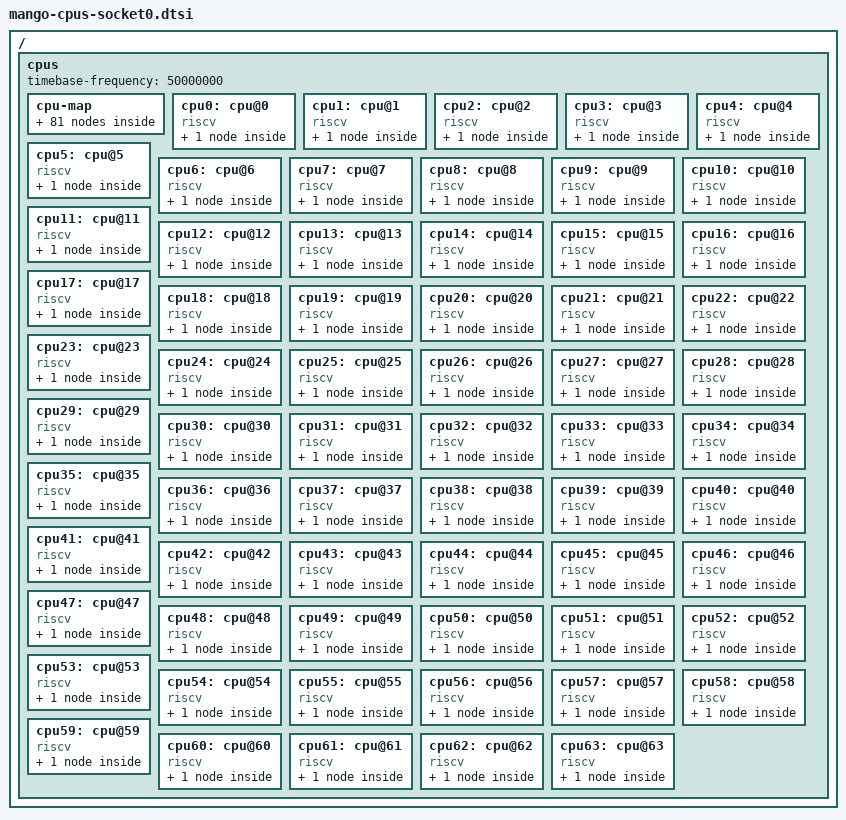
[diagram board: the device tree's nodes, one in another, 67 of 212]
/ {
	cpus {
		#address-cells = <1>;
		#size-cells = <0>;
		timebase-frequency = <50000000>;

		cpu-map {
			socket0 {
				cluster0 {
					 core0 {
						cpu = <&cpu0>;
					 };
					 core1 {
						cpu = <&cpu1>;
					 };
					 core2 {
						cpu = <&cpu2>;
					 };
					 core3 {
						cpu = <&cpu3>;
					 };
				};

				cluster1 {
					 core0 {
						cpu = <&cpu4>;
					 };
					 core1 {
						cpu = <&cpu5>;
					 };
					 core2 {
						cpu = <&cpu6>;
					 };
					 core3 {
						cpu = <&cpu7>;
					 };
				};

				cluster2 {
					 core0 {
						cpu = <&cpu16>;
					 };
					 core1 {
						cpu = <&cpu17>;
					 };
					 core2 {
						cpu = <&cpu18>;
					 };
					 core3 {
						cpu = <&cpu19>;
					 };
				};

				cluster3 {
					 core0 {
						cpu = <&cpu20>;
					 };
					 core1 {
						cpu = <&cpu21>;
					 };
					 core2 {
						cpu = <&cpu22>;
					 };
					 core3 {
						cpu = <&cpu23>;
					 };
				};

				cluster4 {
					 core0 {
						cpu = <&cpu8>;
					 };
					 core1 {
						cpu = <&cpu9>;
					 };
					 core2 {
						cpu = <&cpu10>;
					 };
					 core3 {
						cpu = <&cpu11>;
					 };
				};

				cluster5 {
					 core0 {
						cpu = <&cpu12>;
					 };
					 core1 {
						cpu = <&cpu13>;
					 };
					 core2 {
						cpu = <&cpu14>;
					 };
					 core3 {
						cpu = <&cpu15>;
					 };
				};

				cluster6 {
					 core0 {
						cpu = <&cpu24>;
					 };
					 core1 {
						cpu = <&cpu25>;
					 };
					 core2 {
						cpu = <&cpu26>;
					 };
					 core3 {
						cpu = <&cpu27>;
					 };
				};

				cluster7 {
					 core0 {
						cpu = <&cpu28>;
					 };
					 core1 {
						cpu = <&cpu29>;
					 };
					 core2 {
						cpu = <&cpu30>;
					 };
					 core3 {
						cpu = <&cpu31>;
					 };
				};

				cluster8 {
					 core0 {
						cpu = <&cpu32>;
					 };
					 core1 {
						cpu = <&cpu33>;
					 };
					 core2 {
						cpu = <&cpu34>;
					 };
					 core3 {
						cpu = <&cpu35>;
					 };
				};

				cluster9 {
					 core0 {
						cpu = <&cpu36>;
					 };
					 core1 {
						cpu = <&cpu37>;
					 };
					 core2 {
						cpu = <&cpu38>;
					 };
					 core3 {
						cpu = <&cpu39>;
					 };
				};

				cluster10 {
					 core0 {
						cpu = <&cpu48>;
					 };
					 core1 {
						cpu = <&cpu49>;
					 };
					 core2 {
						cpu = <&cpu50>;
					 };
					 core3 {
						cpu = <&cpu51>;
					 };
				};

				cluster11 {
					 core0 {
						cpu = <&cpu52>;
					 };
					 core1 {
						cpu = <&cpu53>;
					 };
					 core2 {
						cpu = <&cpu54>;
					 };
					 core3 {
						cpu = <&cpu55>;
					 };
				};

				cluster12 {
					 core0 {
						cpu = <&cpu40>;
					 };
					 core1 {
						cpu = <&cpu41>;
					 };
					 core2 {
						cpu = <&cpu42>;
					 };
					 core3 {
						cpu = <&cpu43>;
					 };
				};

				cluster13 {
					 core0 {
						cpu = <&cpu44>;
					 };
					 core1 {
						cpu = <&cpu45>;
					 };
					 core2 {
						cpu = <&cpu46>;
					 };
					 core3 {
						cpu = <&cpu47>;
					 };
				};

				cluster14 {
					 core0 {
						cpu = <&cpu56>;
					 };
					 core1 {
						cpu = <&cpu57>;
					 };
					 core2 {
						cpu = <&cpu58>;
					 };
					 core3 {
						cpu = <&cpu59>;
					 };
				};

				cluster15 {
					 core0 {
						cpu = <&cpu60>;
					 };
					 core1 {
						cpu = <&cpu61>;
					 };
					 core2 {
						cpu = <&cpu62>;
					 };
					 core3 {
						cpu = <&cpu63>;
					 };
				};
			};
		};

		cpu0: cpu@0 {
			device_type = "cpu";
			reg = <0>;
			status = "okay";
			compatible = "riscv";
			riscv,isa = "rv64imafdcv";
			mmu-type = "riscv,sv39";
			numa-node-id = <0>;
			cpu0_intc: interrupt-controller {
				#interrupt-cells = <1>;
				compatible = "riscv,cpu-intc";
				interrupt-controller;
			};
		};
		cpu1: cpu@1 {
			device_type = "cpu";
			reg = <1>;
			status = "okay";
			compatible = "riscv";
			riscv,isa = "rv64imafdcv";
			mmu-type = "riscv,sv39";
			numa-node-id = <0>;
			cpu1_intc: interrupt-controller {
				#interrupt-cells = <1>;
				compatible = "riscv,cpu-intc";
				interrupt-controller;
			};
		};
		cpu2: cpu@2 {
			device_type = "cpu";
			reg = <2>;
			status = "okay";
			compatible = "riscv";
			riscv,isa = "rv64imafdcv";
			mmu-type = "riscv,sv39";
			numa-node-id = <0>;
			cpu2_intc: interrupt-controller {
				#interrupt-cells = <1>;
				compatible = "riscv,cpu-intc";
				interrupt-controller;
			};
		};
		cpu3: cpu@3 {
			device_type = "cpu";
			reg = <3>;
			status = "okay";
			compatible = "riscv";
			riscv,isa = "rv64imafdcv";
			mmu-type = "riscv,sv39";
			numa-node-id = <0>;
			cpu3_intc: interrupt-controller {
				#interrupt-cells = <1>;
				compatible = "riscv,cpu-intc";
				interrupt-controller;
			};
		};
		cpu4: cpu@4 {
			device_type = "cpu";
			reg = <4>;
			status = "okay";
			compatible = "riscv";
			riscv,isa = "rv64imafdcv";
			mmu-type = "riscv,sv39";
			numa-node-id = <0>;
			cpu4_intc: interrupt-controller {
				#interrupt-cells = <1>;
				compatible = "riscv,cpu-intc";
				interrupt-controller;
			};
		};
		cpu5: cpu@5 {
			device_type = "cpu";
			reg = <5>;
			status = "okay";
			compatible = "riscv";
			riscv,isa = "rv64imafdcv";
			mmu-type = "riscv,sv39";
			numa-node-id = <0>;
			cpu5_intc: interrupt-controller {
				#interrupt-cells = <1>;
				compatible = "riscv,cpu-intc";
				interrupt-controller;
			};
		};
		cpu6: cpu@6 {
			device_type = "cpu";
			reg = <6>;
			status = "okay";
			compatible = "riscv";
			riscv,isa = "rv64imafdcv";
			mmu-type = "riscv,sv39";
			numa-node-id = <0>;
			cpu6_intc: interrupt-controller {
				#interrupt-cells = <1>;
				compatible = "riscv,cpu-intc";
				interrupt-controller;
			};
		};
		cpu7: cpu@7 {
			device_type = "cpu";
			reg = <7>;
			status = "okay";
			compatible = "riscv";
			riscv,isa = "rv64imafdcv";
			mmu-type = "riscv,sv39";
			numa-node-id = <0>;
			cpu7_intc: interrupt-controller {
				#interrupt-cells = <1>;
				compatible = "riscv,cpu-intc";
				interrupt-controller;
			};
		};
		cpu8: cpu@8 {
			device_type = "cpu";
			reg = <8>;
			status = "okay";
			compatible = "riscv";
			riscv,isa = "rv64imafdcv";
			mmu-type = "riscv,sv39";
			numa-node-id = <1>;
			cpu8_intc: interrupt-controller {
				#interrupt-cells = <1>;
				compatible = "riscv,cpu-intc";
				interrupt-controller;
			};
		};
		cpu9: cpu@9 {
			device_type = "cpu";
			reg = <9>;
			status = "okay";
			compatible = "riscv";
			riscv,isa = "rv64imafdcv";
			mmu-type = "riscv,sv39";
			numa-node-id = <1>;
			cpu9_intc: interrupt-controller {
				#interrupt-cells = <1>;
				compatible = "riscv,cpu-intc";
				interrupt-controller;
			};
		};
		cpu10: cpu@10 {
			device_type = "cpu";
			reg = <10>;
			status = "okay";
			compatible = "riscv";
			riscv,isa = "rv64imafdcv";
			mmu-type = "riscv,sv39";
			numa-node-id = <1>;
			cpu10_intc: interrupt-controller {
				#interrupt-cells = <1>;
				compatible = "riscv,cpu-intc";
				interrupt-controller;
			};
		};
		cpu11: cpu@11 {
			device_type = "cpu";
			reg = <11>;
			status = "okay";
			compatible = "riscv";
			riscv,isa = "rv64imafdcv";
			mmu-type = "riscv,sv39";
			numa-node-id = <1>;
			cpu11_intc: interrupt-controller {
				#interrupt-cells = <1>;
				compatible = "riscv,cpu-intc";
				interrupt-controller;
			};
		};
		cpu12: cpu@12 {
			device_type = "cpu";
			reg = <12>;
			status = "okay";
			compatible = "riscv";
			riscv,isa = "rv64imafdcv";
			mmu-type = "riscv,sv39";
			numa-node-id = <1>;
			cpu12_intc: interrupt-controller {
				#interrupt-cells = <1>;
				compatible = "riscv,cpu-intc";
				interrupt-controller;
			};
		};
		cpu13: cpu@13 {
			device_type = "cpu";
			reg = <13>;
			status = "okay";
			compatible = "riscv";
			riscv,isa = "rv64imafdcv";
			mmu-type = "riscv,sv39";
			numa-node-id = <1>;
			cpu13_intc: interrupt-controller {
				#interrupt-cells = <1>;
				compatible = "riscv,cpu-intc";
				interrupt-controller;
			};
		};
		cpu14: cpu@14 {
			device_type = "cpu";
			reg = <14>;
			status = "okay";
			compatible = "riscv";
			riscv,isa = "rv64imafdcv";
			mmu-type = "riscv,sv39";
			numa-node-id = <1>;
			cpu14_intc: interrupt-controller {
				#interrupt-cells = <1>;
				compatible = "riscv,cpu-intc";
				interrupt-controller;
			};
		};
		cpu15: cpu@15 {
			device_type = "cpu";
			reg = <15>;
			status = "okay";
			compatible = "riscv";
			riscv,isa = "rv64imafdcv";
			mmu-type = "riscv,sv39";
			numa-node-id = <1>;
			cpu15_intc: interrupt-controller {
				#interrupt-cells = <1>;
				compatible = "riscv,cpu-intc";
				interrupt-controller;
			};
		};
		cpu16: cpu@16 {
			device_type = "cpu";
			reg = <16>;
			status = "okay";
			compatible = "riscv";
			riscv,isa = "rv64imafdcv";
			mmu-type = "riscv,sv39";
			numa-node-id = <0>;
			cpu16_intc: interrupt-controller {
				#interrupt-cells = <1>;
				compatible = "riscv,cpu-intc";
				interrupt-controller;
			};
		};
		cpu17: cpu@17 {
			device_type = "cpu";
			reg = <17>;
			status = "okay";
			compatible = "riscv";
			riscv,isa = "rv64imafdcv";
			mmu-type = "riscv,sv39";
			numa-node-id = <0>;
			cpu17_intc: interrupt-controller {
				#interrupt-cells = <1>;
				compatible = "riscv,cpu-intc";
				interrupt-controller;
			};
		};
		cpu18: cpu@18 {
			device_type = "cpu";
			reg = <18>;
			status = "okay";
			compatible = "riscv";
			riscv,isa = "rv64imafdcv";
			mmu-type = "riscv,sv39";
			numa-node-id = <0>;
			cpu18_intc: interrupt-controller {
				#interrupt-cells = <1>;
				compatible = "riscv,cpu-intc";
				interrupt-controller;
			};
		};
		cpu19: cpu@19 {
			device_type = "cpu";
			reg = <19>;
			status = "okay";
			compatible = "riscv";
			riscv,isa = "rv64imafdcv";
			mmu-type = "riscv,sv39";
			numa-node-id = <0>;
			cpu19_intc: interrupt-controller {
				#interrupt-cells = <1>;
				compatible = "riscv,cpu-intc";
				interrupt-controller;
			};
		};
		cpu20: cpu@20 {
			device_type = "cpu";
			reg = <20>;
			status = "okay";
			compatible = "riscv";
			riscv,isa = "rv64imafdcv";
			mmu-type = "riscv,sv39";
			numa-node-id = <0>;
			cpu20_intc: interrupt-controller {
				#interrupt-cells = <1>;
				compatible = "riscv,cpu-intc";
				interrupt-controller;
			};
		};
		cpu21: cpu@21 {
			device_type = "cpu";
			reg = <21>;
			status = "okay";
			compatible = "riscv";
			riscv,isa = "rv64imafdcv";
			mmu-type = "riscv,sv39";
			numa-node-id = <0>;
			cpu21_intc: interrupt-controller {
				#interrupt-cells = <1>;
				compatible = "riscv,cpu-intc";
				interrupt-controller;
			};
		};
		cpu22: cpu@22 {
			device_type = "cpu";
			reg = <22>;
			status = "okay";
			compatible = "riscv";
			riscv,isa = "rv64imafdcv";
			mmu-type = "riscv,sv39";
			numa-node-id = <0>;
			cpu22_intc: interrupt-controller {
				#interrupt-cells = <1>;
				compatible = "riscv,cpu-intc";
				interrupt-controller;
			};
		};
		cpu23: cpu@23 {
			device_type = "cpu";
			reg = <23>;
			status = "okay";
			compatible = "riscv";
			riscv,isa = "rv64imafdcv";
			mmu-type = "riscv,sv39";
			numa-node-id = <0>;
			cpu23_intc: interrupt-controller {
				#interrupt-cells = <1>;
				compatible = "riscv,cpu-intc";
				interrupt-controller;
			};
		};
		cpu24: cpu@24 {
			device_type = "cpu";
			reg = <24>;
			status = "okay";
			compatible = "riscv";
			riscv,isa = "rv64imafdcv";
			mmu-type = "riscv,sv39";
			numa-node-id = <1>;
			cpu24_intc: interrupt-controller {
				#interrupt-cells = <1>;
				compatible = "riscv,cpu-intc";
				interrupt-controller;
			};
		};
		cpu25: cpu@25 {
			device_type = "cpu";
			reg = <25>;
			status = "okay";
			compatible = "riscv";
			riscv,isa = "rv64imafdcv";
			mmu-type = "riscv,sv39";
			numa-node-id = <1>;
			cpu25_intc: interrupt-controller {
				#interrupt-cells = <1>;
				compatible = "riscv,cpu-intc";
				interrupt-controller;
			};
		};
		cpu26: cpu@26 {
			device_type = "cpu";
			reg = <26>;
			status = "okay";
			compatible = "riscv";
			riscv,isa = "rv64imafdcv";
			mmu-type = "riscv,sv39";
			numa-node-id = <1>;
			cpu26_intc: interrupt-controller {
				#interrupt-cells = <1>;
				compatible = "riscv,cpu-intc";
				interrupt-controller;
			};
		};
		cpu27: cpu@27 {
			device_type = "cpu";
			reg = <27>;
			status = "okay";
			compatible = "riscv";
			riscv,isa = "rv64imafdcv";
			mmu-type = "riscv,sv39";
			numa-node-id = <1>;
			cpu27_intc: interrupt-controller {
				#interrupt-cells = <1>;
				compatible = "riscv,cpu-intc";
				interrupt-controller;
			};
		};
		cpu28: cpu@28 {
			device_type = "cpu";
			reg = <28>;
			status = "okay";
			compatible = "riscv";
			riscv,isa = "rv64imafdcv";
			mmu-type = "riscv,sv39";
			numa-node-id = <1>;
			cpu28_intc: interrupt-controller {
				#interrupt-cells = <1>;
				compatible = "riscv,cpu-intc";
				interrupt-controller;
			};
		};
		cpu29: cpu@29 {
			device_type = "cpu";
			reg = <29>;
			status = "okay";
			compatible = "riscv";
			riscv,isa = "rv64imafdcv";
			mmu-type = "riscv,sv39";
			numa-node-id = <1>;
			cpu29_intc: interrupt-controller {
				#interrupt-cells = <1>;
				compatible = "riscv,cpu-intc";
				interrupt-controller;
			};
		};
		cpu30: cpu@30 {
			device_type = "cpu";
			reg = <30>;
			status = "okay";
			compatible = "riscv";
			riscv,isa = "rv64imafdcv";
			mmu-type = "riscv,sv39";
			numa-node-id = <1>;
			cpu30_intc: interrupt-controller {
				#interrupt-cells = <1>;
				compatible = "riscv,cpu-intc";
				interrupt-controller;
			};
		};
		cpu31: cpu@31 {
			device_type = "cpu";
			reg = <31>;
			status = "okay";
			compatible = "riscv";
			riscv,isa = "rv64imafdcv";
			mmu-type = "riscv,sv39";
			numa-node-id = <1>;
			cpu31_intc: interrupt-controller {
				#interrupt-cells = <1>;
				compatible = "riscv,cpu-intc";
				interrupt-controller;
			};
		};
		cpu32: cpu@32 {
			device_type = "cpu";
			reg = <32>;
			status = "okay";
			compatible = "riscv";
			riscv,isa = "rv64imafdcv";
			mmu-type = "riscv,sv39";
			numa-node-id = <2>;
			cpu32_intc: interrupt-controller {
				#interrupt-cells = <1>;
				compatible = "riscv,cpu-intc";
				interrupt-controller;
			};
		};
		cpu33: cpu@33 {
			device_type = "cpu";
			reg = <33>;
			status = "okay";
			compatible = "riscv";
			riscv,isa = "rv64imafdcv";
			mmu-type = "riscv,sv39";
			numa-node-id = <2>;
			cpu33_intc: interrupt-controller {
				#interrupt-cells = <1>;
				compatible = "riscv,cpu-intc";
				interrupt-controller;
			};
		};
		cpu34: cpu@34 {
			device_type = "cpu";
			reg = <34>;
			status = "okay";
			compatible = "riscv";
			riscv,isa = "rv64imafdcv";
			mmu-type = "riscv,sv39";
			numa-node-id = <2>;
			cpu34_intc: interrupt-controller {
				#interrupt-cells = <1>;
				compatible = "riscv,cpu-intc";
				interrupt-controller;
			};
		};
		cpu35: cpu@35 {
			device_type = "cpu";
			reg = <35>;
			status = "okay";
			compatible = "riscv";
			riscv,isa = "rv64imafdcv";
			mmu-type = "riscv,sv39";
			numa-node-id = <2>;
			cpu35_intc: interrupt-controller {
				#interrupt-cells = <1>;
				compatible = "riscv,cpu-intc";
				interrupt-controller;
			};
		};
		cpu36: cpu@36 {
			device_type = "cpu";
			reg = <36>;
			status = "okay";
			compatible = "riscv";
			riscv,isa = "rv64imafdcv";
			mmu-type = "riscv,sv39";
			numa-node-id = <2>;
			cpu36_intc: interrupt-controller {
				#interrupt-cells = <1>;
				compatible = "riscv,cpu-intc";
				interrupt-controller;
			};
		};
		cpu37: cpu@37 {
			device_type = "cpu";
			reg = <37>;
			status = "okay";
			compatible = "riscv";
			riscv,isa = "rv64imafdcv";
			mmu-type = "riscv,sv39";
			numa-node-id = <2>;
			cpu37_intc: interrupt-controller {
				#interrupt-cells = <1>;
				compatible = "riscv,cpu-intc";
				interrupt-controller;
			};
		};
		cpu38: cpu@38 {
			device_type = "cpu";
			reg = <38>;
			status = "okay";
			compatible = "riscv";
			riscv,isa = "rv64imafdcv";
			mmu-type = "riscv,sv39";
			numa-node-id = <2>;
			cpu38_intc: interrupt-controller {
				#interrupt-cells = <1>;
				compatible = "riscv,cpu-intc";
				interrupt-controller;
			};
		};
		cpu39: cpu@39 {
			device_type = "cpu";
			reg = <39>;
			status = "okay";
			compatible = "riscv";
			riscv,isa = "rv64imafdcv";
			mmu-type = "riscv,sv39";
			numa-node-id = <2>;
			cpu39_intc: interrupt-controller {
				#interrupt-cells = <1>;
				compatible = "riscv,cpu-intc";
				interrupt-controller;
			};
		};
		cpu40: cpu@40 {
			device_type = "cpu";
			reg = <40>;
			status = "okay";
			compatible = "riscv";
			riscv,isa = "rv64imafdcv";
			mmu-type = "riscv,sv39";
			numa-node-id = <3>;
			cpu40_intc: interrupt-controller {
				#interrupt-cells = <1>;
				compatible = "riscv,cpu-intc";
				interrupt-controller;
			};
		};
		cpu41: cpu@41 {
			device_type = "cpu";
			reg = <41>;
			status = "okay";
			compatible = "riscv";
			riscv,isa = "rv64imafdcv";
			mmu-type = "riscv,sv39";
			numa-node-id = <3>;
			cpu41_intc: interrupt-controller {
				#interrupt-cells = <1>;
				compatible = "riscv,cpu-intc";
				interrupt-controller;
			};
		};
		cpu42: cpu@42 {
			device_type = "cpu";
			reg = <42>;
			status = "okay";
			compatible = "riscv";
			riscv,isa = "rv64imafdcv";
			mmu-type = "riscv,sv39";
			numa-node-id = <3>;
			cpu42_intc: interrupt-controller {
				#interrupt-cells = <1>;
				compatible = "riscv,cpu-intc";
				interrupt-controller;
			};
		};
		cpu43: cpu@43 {
			device_type = "cpu";
			reg = <43>;
			status = "okay";
			compatible = "riscv";
			riscv,isa = "rv64imafdcv";
			mmu-type = "riscv,sv39";
			numa-node-id = <3>;
			cpu43_intc: interrupt-controller {
				#interrupt-cells = <1>;
				compatible = "riscv,cpu-intc";
				interrupt-controller;
			};
		};
		cpu44: cpu@44 {
			device_type = "cpu";
			reg = <44>;
			status = "okay";
			compatible = "riscv";
			riscv,isa = "rv64imafdcv";
			mmu-type = "riscv,sv39";
			numa-node-id = <3>;
			cpu44_intc: interrupt-controller {
				#interrupt-cells = <1>;
				compatible = "riscv,cpu-intc";
				interrupt-controller;
			};
		};
		cpu45: cpu@45 {
			device_type = "cpu";
			reg = <45>;
			status = "okay";
			compatible = "riscv";
			riscv,isa = "rv64imafdcv";
			mmu-type = "riscv,sv39";
			numa-node-id = <3>;
			cpu45_intc: interrupt-controller {
				#interrupt-cells = <1>;
				compatible = "riscv,cpu-intc";
				interrupt-controller;
			};
		};
		cpu46: cpu@46 {
			device_type = "cpu";
			reg = <46>;
			status = "okay";
			compatible = "riscv";
			riscv,isa = "rv64imafdcv";
			mmu-type = "riscv,sv39";
			numa-node-id = <3>;
			cpu46_intc: interrupt-controller {
				#interrupt-cells = <1>;
				compatible = "riscv,cpu-intc";
				interrupt-controller;
			};
		};
		cpu47: cpu@47 {
			device_type = "cpu";
			reg = <47>;
			status = "okay";
			compatible = "riscv";
			riscv,isa = "rv64imafdcv";
			mmu-type = "riscv,sv39";
			numa-node-id = <3>;
			cpu47_intc: interrupt-controller {
				#interrupt-cells = <1>;
				compatible = "riscv,cpu-intc";
				interrupt-controller;
			};
		};
		cpu48: cpu@48 {
			device_type = "cpu";
			reg = <48>;
			status = "okay";
			compatible = "riscv";
			riscv,isa = "rv64imafdcv";
			mmu-type = "riscv,sv39";
			numa-node-id = <2>;
			cpu48_intc: interrupt-controller {
				#interrupt-cells = <1>;
				compatible = "riscv,cpu-intc";
				interrupt-controller;
			};
		};
		cpu49: cpu@49 {
			device_type = "cpu";
			reg = <49>;
			status = "okay";
			compatible = "riscv";
			riscv,isa = "rv64imafdcv";
			mmu-type = "riscv,sv39";
			numa-node-id = <2>;
			cpu49_intc: interrupt-controller {
				#interrupt-cells = <1>;
				compatible = "riscv,cpu-intc";
				interrupt-controller;
			};
		};
		cpu50: cpu@50 {
			device_type = "cpu";
			reg = <50>;
			status = "okay";
			compatible = "riscv";
			riscv,isa = "rv64imafdcv";
			mmu-type = "riscv,sv39";
			numa-node-id = <2>;
			cpu50_intc: interrupt-controller {
				#interrupt-cells = <1>;
				compatible = "riscv,cpu-intc";
				interrupt-controller;
			};
		};
		cpu51: cpu@51 {
			device_type = "cpu";
			reg = <51>;
			status = "okay";
			compatible = "riscv";
			riscv,isa = "rv64imafdcv";
			mmu-type = "riscv,sv39";
			numa-node-id = <2>;
			cpu51_intc: interrupt-controller {
				#interrupt-cells = <1>;
				compatible = "riscv,cpu-intc";
				interrupt-controller;
			};
		};
		cpu52: cpu@52 {
			device_type = "cpu";
			reg = <52>;
			status = "okay";
			compatible = "riscv";
			riscv,isa = "rv64imafdcv";
			mmu-type = "riscv,sv39";
			numa-node-id = <2>;
			cpu52_intc: interrupt-controller {
				#interrupt-cells = <1>;
				compatible = "riscv,cpu-intc";
				interrupt-controller;
			};
		};
		cpu53: cpu@53 {
			device_type = "cpu";
			reg = <53>;
			status = "okay";
			compatible = "riscv";
			riscv,isa = "rv64imafdcv";
			mmu-type = "riscv,sv39";
			numa-node-id = <2>;
			cpu53_intc: interrupt-controller {
				#interrupt-cells = <1>;
				compatible = "riscv,cpu-intc";
				interrupt-controller;
			};
		};
		cpu54: cpu@54 {
			device_type = "cpu";
			reg = <54>;
			status = "okay";
			compatible = "riscv";
			riscv,isa = "rv64imafdcv";
			mmu-type = "riscv,sv39";
			numa-node-id = <2>;
			cpu54_intc: interrupt-controller {
				#interrupt-cells = <1>;
				compatible = "riscv,cpu-intc";
				interrupt-controller;
			};
		};
		cpu55: cpu@55 {
			device_type = "cpu";
			reg = <55>;
			status = "okay";
			compatible = "riscv";
			riscv,isa = "rv64imafdcv";
			mmu-type = "riscv,sv39";
			numa-node-id = <2>;
			cpu55_intc: interrupt-controller {
				#interrupt-cells = <1>;
				compatible = "riscv,cpu-intc";
				interrupt-controller;
			};
		};
		cpu56: cpu@56 {
			device_type = "cpu";
			reg = <56>;
			status = "okay";
			compatible = "riscv";
			riscv,isa = "rv64imafdcv";
			mmu-type = "riscv,sv39";
			numa-node-id = <3>;
			cpu56_intc: interrupt-controller {
				#interrupt-cells = <1>;
				compatible = "riscv,cpu-intc";
				interrupt-controller;
			};
		};
		cpu57: cpu@57 {
			device_type = "cpu";
			reg = <57>;
			status = "okay";
			compatible = "riscv";
			riscv,isa = "rv64imafdcv";
			mmu-type = "riscv,sv39";
			numa-node-id = <3>;
			cpu57_intc: interrupt-controller {
				#interrupt-cells = <1>;
				compatible = "riscv,cpu-intc";
				interrupt-controller;
			};
		};
		cpu58: cpu@58 {
			device_type = "cpu";
			reg = <58>;
			status = "okay";
			compatible = "riscv";
			riscv,isa = "rv64imafdcv";
			mmu-type = "riscv,sv39";
			numa-node-id = <3>;
			cpu58_intc: interrupt-controller {
				#interrupt-cells = <1>;
				compatible = "riscv,cpu-intc";
				interrupt-controller;
			};
		};
		cpu59: cpu@59 {
			device_type = "cpu";
			reg = <59>;
			status = "okay";
			compatible = "riscv";
			riscv,isa = "rv64imafdcv";
			mmu-type = "riscv,sv39";
			numa-node-id = <3>;
			cpu59_intc: interrupt-controller {
				#interrupt-cells = <1>;
				compatible = "riscv,cpu-intc";
				interrupt-controller;
			};
		};
		cpu60: cpu@60 {
			device_type = "cpu";
			reg = <60>;
			status = "okay";
			compatible = "riscv";
			riscv,isa = "rv64imafdcv";
			mmu-type = "riscv,sv39";
			numa-node-id = <3>;
			cpu60_intc: interrupt-controller {
				#interrupt-cells = <1>;
				compatible = "riscv,cpu-intc";
				interrupt-controller;
			};
		};
		cpu61: cpu@61 {
			device_type = "cpu";
			reg = <61>;
			status = "okay";
			compatible = "riscv";
			riscv,isa = "rv64imafdcv";
			mmu-type = "riscv,sv39";
			numa-node-id = <3>;
			cpu61_intc: interrupt-controller {
				#interrupt-cells = <1>;
				compatible = "riscv,cpu-intc";
				interrupt-controller;
			};
		};
		cpu62: cpu@62 {
			device_type = "cpu";
			reg = <62>;
			status = "okay";
			compatible = "riscv";
			riscv,isa = "rv64imafdcv";
			mmu-type = "riscv,sv39";
			numa-node-id = <3>;
			cpu62_intc: interrupt-controller {
				#interrupt-cells = <1>;
				compatible = "riscv,cpu-intc";
				interrupt-controller;
			};
		};
		cpu63: cpu@63 {
			device_type = "cpu";
			reg = <63>;
			status = "okay";
			compatible = "riscv";
			riscv,isa = "rv64imafdcv";
			mmu-type = "riscv,sv39";
			numa-node-id = <3>;
			cpu63_intc: interrupt-controller {
				#interrupt-cells = <1>;
				compatible = "riscv,cpu-intc";
				interrupt-controller;
			};
		};
	};
};
